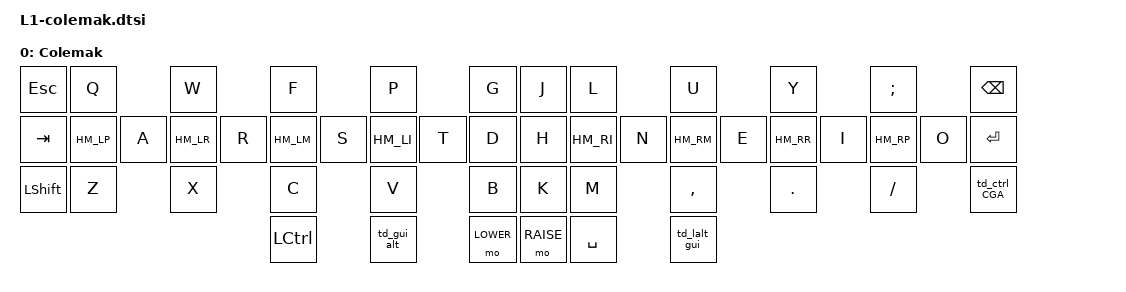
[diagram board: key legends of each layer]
/**
 *
 */

/ {
  keymap {
    compatible = "zmk,keymap";

    colemak_layer {
        label = "Colemak";
        bindings = <
// ╭───────────────┬───────────────┬───────────────┬───────────────┬───────────────┬───────────────╮   ╭───────────────┬───────────────┬───────────────┬───────────────┬───────────────┬───────────────╮
    &kp ESC         &kp Q           &kp W           &kp F           &kp P           &kp G               &kp J           &kp L           &kp U           &kp Y           &kp SEMI        &kp BSPC
// ├───────────────├───────────────┼───────────────┼───────────────┼───────────────┼───────────────┤   ├───────────────├───────────────┼───────────────┼───────────────┼───────────────┼───────────────┤
    &kp TAB			HM_LP A      	HM_LR R      	HM_LM S      	HM_LI T      	&kp D               &kp H           HM_RI N     	HM_RM E   		HM_RR I      	HM_RP O			&kp ENTER
// ├───────────────├───────────────┼───────────────┼───────────────┼───────────────┼───────────────┤   ├───────────────├───────────────┼───────────────┼───────────────┼───────────────┼───────────────┤
    &kp LSHFT 		&kp Z     		&kp X      		&kp C      		&kp V       	&kp B               &kp K           &kp M       	&kp COMMA  		&kp DOT   		&kp FSLH  		&td_ctrl_CGA
// ╰───────────────┴───────────────┴───────────────┼───────────────┼───────────────┼───────────────┤   ├───────────────├───────────────┼───────────────┼───────────────┴───────────────┴───────────────╯
                                                    &kp LCTRL       &td_gui_alt		&mo LOWER			&mo RAISE		&kp SPACE 		&td_lalt_gui
//                                                 ╰───────────────┴───────────────┴───────────────╯   ╰───────────────┴───────────────┴───────────────╯
			>;
		};
    };
};
